# N32H49X register map
Vendor: Nsingtech Ltd.; File version: 1.0
Registers are 32-bit, read-write, reset 0x0 unless marked. A register's access mark holds for its fields unless they carry their own. Offsets are from the block's base; [hi:lo] are bit positions; {n}, {i} and the like mark numbered series.

## GTIM1 — General purpose timer 1
Base 0x40002C00
Same registers: GTIM4 0x40003800
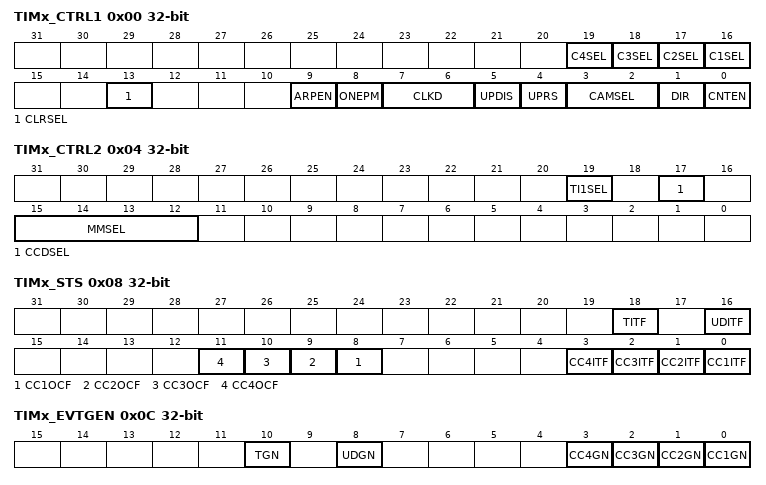
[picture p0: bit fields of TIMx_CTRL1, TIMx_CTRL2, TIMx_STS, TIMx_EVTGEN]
0x00 TIMx_CTRL1
  [n+15] C{n}SEL (n=1..4), [13] CLRSEL, [9] ARPEN, [8] ONEPM, [7:6] CLKD, [5] UPDIS, [4] UPRS, [3:2] CAMSEL, [1] DIR, [0] CNTEN
0x04 TIMx_CTRL2
  [19] TI1SEL, [17] CCDSEL, [15:12] MMSEL
0x08 TIMx_STS
  [18] TITF, [16] UDITF, [n+7] CC{n}OCF (n=1..4), [n-1] CC{n}ITF (n=1..4)
0x0C TIMx_EVTGEN
  [10] TGN, [8] UDGN, [n-1] CC{n}GN (n=1..4)
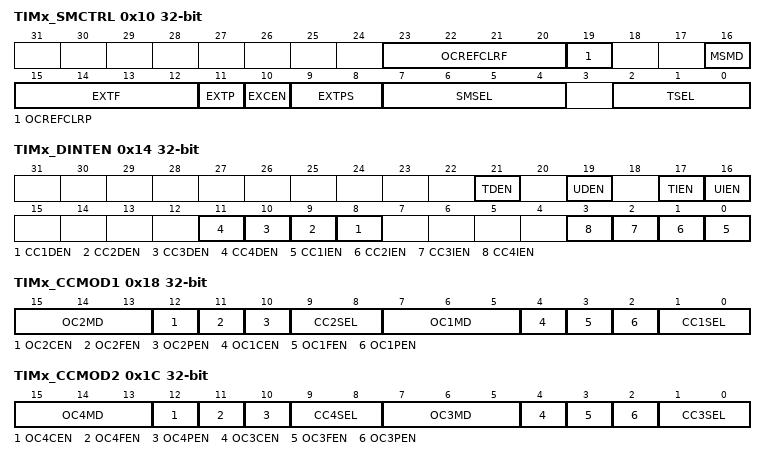
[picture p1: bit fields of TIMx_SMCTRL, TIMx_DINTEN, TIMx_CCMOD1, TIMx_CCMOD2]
0x10 TIMx_SMCTRL
  [23:20] OCREFCLRF, [19] OCREFCLRP, [16] MSMD, [15:12] EXTF, [11] EXTP, [10] EXCEN, [9:8] EXTPS, [7:4] SMSEL, [2:0] TSEL
0x14 TIMx_DINTEN
  [21] TDEN, [19] UDEN, [17] TIEN, [16] UIEN, [n+7] CC{n}DEN (n=1..4), [n-1] CC{n}IEN (n=1..4)
0x18 TIMx_CCMOD1
  [15:13] OC2MD, [12] OC2CEN, [11] OC2FEN, [10] OC2PEN, [9:8] CC2SEL, [7:5] OC1MD, [4] OC1CEN, [3] OC1FEN, [2] OC1PEN, [1:0] CC1SEL
0x1C TIMx_CCMOD2
  [15:13] OC4MD, [12] OC4CEN, [11] OC4FEN, [10] OC4PEN, [9:8] CC4SEL, [7:5] OC3MD, [4] OC3CEN, [3] OC3FEN, [2] OC3PEN, [1:0] CC3SEL
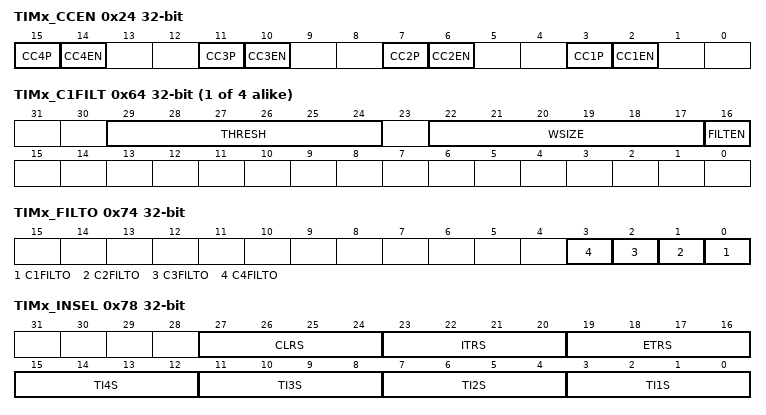
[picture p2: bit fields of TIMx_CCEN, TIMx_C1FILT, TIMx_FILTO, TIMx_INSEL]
0x24 TIMx_CCEN
  [4n-1] CC{n}P (n=1..4), [4n-2] CC{n}EN (n=1..4)
{0x24+4i} TIMx_CCDAT{i} (i=1..4)
0x40 TIMx_PSC
0x44 TIMx_AR reset 0xFFFF
0x48 TIMx_CNT
{0x60+4i} TIMx_C{i}FILT (i=1..4)
  [29:24] THRESH, [22:17] WSIZE, [16] FILTEN
0x74 TIMx_FILTO
  [n-1] C{n}FILTO (n=1..4)
0x78 TIMx_INSEL
  [27:24] CLRS, [23:20] ITRS, [19:16] ETRS, [4n-1:4n-4] TI{n}S (n=1..4)
0x88 TIMx_SLIDFPSC
  [15:0] SLIDFPSC
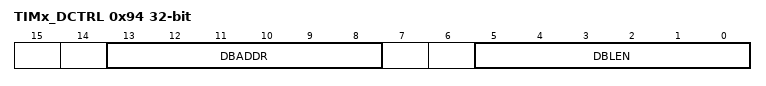
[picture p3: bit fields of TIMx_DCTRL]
0x94 TIMx_DCTRL
  [13:8] DBADDR, [5:0] DBLEN
0x98 TIMx_DADDR
  [31:0] BURST

## GTIM2 — General purpose timer 2
Base 0x40003000
Same registers: GTIM3 0x40003400, GTIM5 0x40005C00, GTIM6 0x40006000, GTIM7 0x40006400
Registers as GTIM1; these are added or differ:
{0x24+4i} TIMx_CCDAT{i} (i=1..4)
  [15:0] CCDAT{i}
0x40 TIMx_PSC
  [15:0] PSC
0x44 TIMx_AR reset 0xFFFF
  [15:0] AR
0x48 TIMx_CNT
  [15:0] CNT

## GTIM8 — General purpose timer 8
Base 0x40010C00
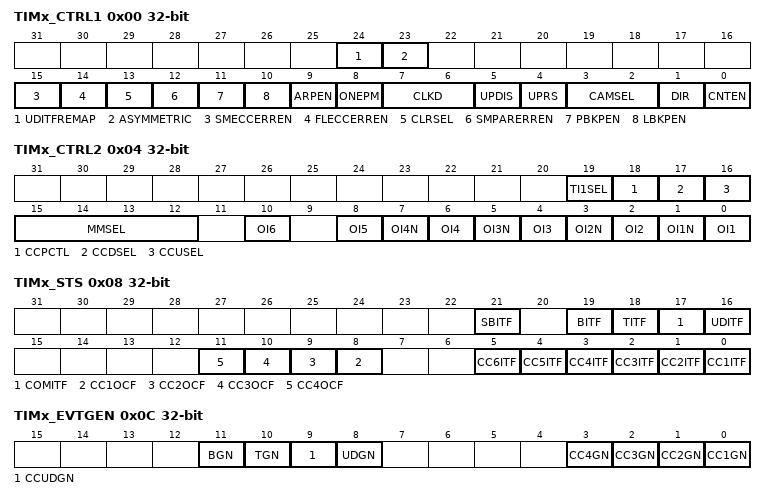
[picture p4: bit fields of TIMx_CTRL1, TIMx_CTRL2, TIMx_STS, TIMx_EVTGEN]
0x00 TIMx_CTRL1
  [24] UDITFREMAP, [23] ASYMMETRIC, [15] SMECCERREN, [14] FLECCERREN, [13] CLRSEL, [12] SMPARERREN, [11] PBKPEN, [10] LBKPEN, [9] ARPEN, [8] ONEPM, [7:6] CLKD, [5] UPDIS, [4] UPRS, [3:2] CAMSEL, [1] DIR, [0] CNTEN
0x04 TIMx_CTRL2
  [19] TI1SEL, [18] CCPCTL, [17] CCDSEL, [16] CCUSEL, [15:12] MMSEL, [2n-2] OI{n} (n=1..6), [2n-1] OI{n}N (n=1..4)
0x08 TIMx_STS
  [21] SBITF, [19] BITF, [18] TITF, [17] COMITF, [16] UDITF, [n+7] CC{n}OCF (n=1..4), [n-1] CC{n}ITF (n=1..6)
0x0C TIMx_EVTGEN
  [11] BGN, [10] TGN, [9] CCUDGN, [8] UDGN, [n-1] CC{n}GN (n=1..4)
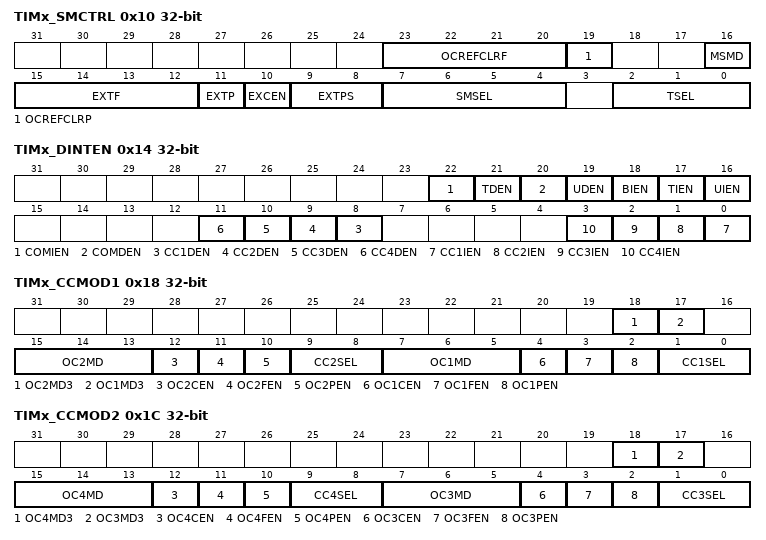
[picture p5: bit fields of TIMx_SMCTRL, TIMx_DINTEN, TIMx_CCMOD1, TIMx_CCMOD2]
0x10 TIMx_SMCTRL
  [23:20] OCREFCLRF, [19] OCREFCLRP, [16] MSMD, [15:12] EXTF, [11] EXTP, [10] EXCEN, [9:8] EXTPS, [7:4] SMSEL, [2:0] TSEL
0x14 TIMx_DINTEN
  [22] COMIEN, [21] TDEN, [20] COMDEN, [19] UDEN, [18] BIEN, [17] TIEN, [16] UIEN, [n+7] CC{n}DEN (n=1..4), [n-1] CC{n}IEN (n=1..4)
0x18 TIMx_CCMOD1
  [18] OC2MD3, [17] OC1MD3, [15:13] OC2MD, [12] OC2CEN, [11] OC2FEN, [10] OC2PEN, [9:8] CC2SEL, [7:5] OC1MD, [4] OC1CEN, [3] OC1FEN, [2] OC1PEN, [1:0] CC1SEL
0x1C TIMx_CCMOD2
  [18] OC4MD3, [17] OC3MD3, [15:13] OC4MD, [12] OC4CEN, [11] OC4FEN, [10] OC4PEN, [9:8] CC4SEL, [7:5] OC3MD, [4] OC3CEN, [3] OC3FEN, [2] OC3PEN, [1:0] CC3SEL
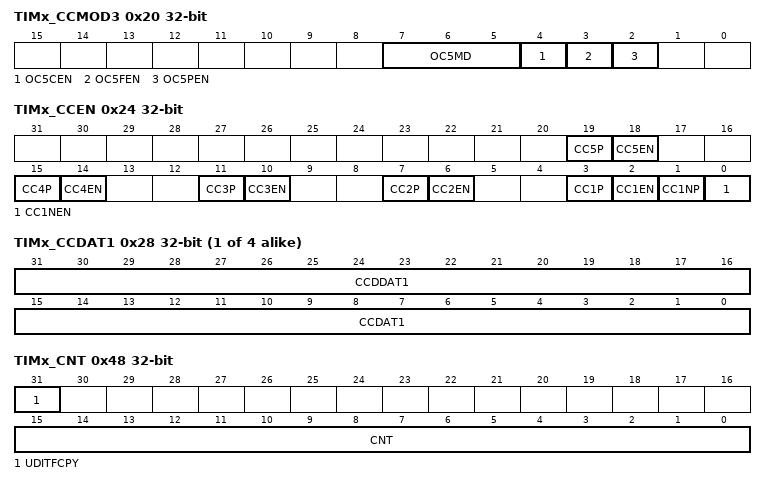
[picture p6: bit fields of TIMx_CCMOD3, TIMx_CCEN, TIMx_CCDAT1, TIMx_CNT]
0x20 TIMx_CCMOD3
  [7:5] OC5MD, [4] OC5CEN, [3] OC5FEN, [2] OC5PEN
0x24 TIMx_CCEN
  [4n-1] CC{n}P (n=1..5), [4n-2] CC{n}EN (n=1..5), [1] CC1NP, [0] CC1NEN
{0x24+4i} TIMx_CCDAT{i} (i=1..4)
  [31:16] CCDDAT{i}, [15:0] CCDAT{i}
0x38 TIMx_CCDAT5
  [15:0] CCDAT5
0x40 TIMx_PSC
  [15:0] PSC
0x44 TIMx_AR reset 0xFFFF
  [15:0] AR
0x48 TIMx_CNT
  [31] UDITFCPY, [15:0] CNT
0x4C TIMx_REPCNT
  [7:0] REPCNT
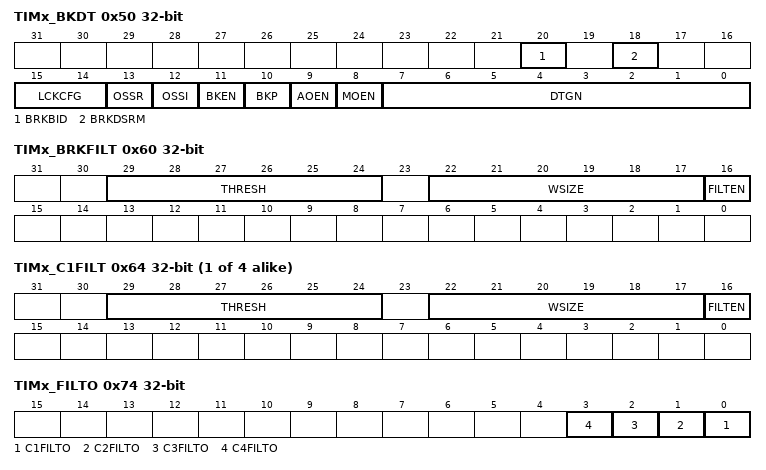
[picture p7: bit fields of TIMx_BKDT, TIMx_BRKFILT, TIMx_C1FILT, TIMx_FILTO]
0x50 TIMx_BKDT
  [20] BRKBID, [18] BRKDSRM, [15:14] LCKCFG, [13] OSSR, [12] OSSI, [11] BKEN, [10] BKP, [9] AOEN, [8] MOEN, [7:0] DTGN
0x60 TIMx_BRKFILT
  [29:24] THRESH, [22:17] WSIZE, [16] FILTEN
{0x60+4i} TIMx_C{i}FILT (i=1..4)
  [29:24] THRESH, [22:17] WSIZE, [16] FILTEN
0x74 TIMx_FILTO
  [n-1] C{n}FILTO (n=1..4)
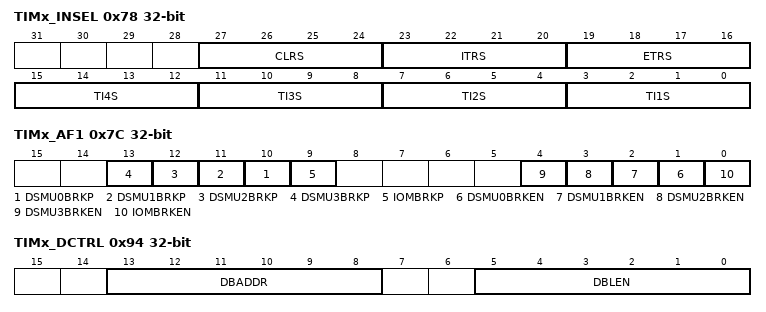
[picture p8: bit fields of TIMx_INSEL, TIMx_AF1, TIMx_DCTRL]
0x78 TIMx_INSEL
  [27:24] CLRS, [23:20] ITRS, [19:16] ETRS, [4n-1:4n-4] TI{n}S (n=1..4)
0x7C TIMx_AF1
  [n+10] DSMU{n}BRKP (n=0..3), [9] IOMBRKP, [n+1] DSMU{n}BRKEN (n=0..3), [0] IOMBRKEN
0x88 TIMx_SLIDFPSC
  [15:0] SLIDFPSC
0x94 TIMx_DCTRL
  [13:8] DBADDR, [5:0] DBLEN
0x98 TIMx_DADDR
  [31:0] BURST

## GTIM9 — General purpose timer 9
Base 0x40011000
Same registers: GTIM10 0x40011400
Registers as GTIM8; these are added or differ:
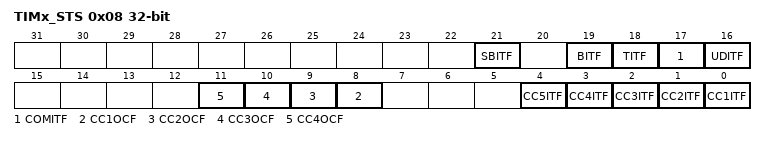
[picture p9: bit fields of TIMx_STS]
0x08 TIMx_STS
  [21] SBITF, [19] BITF, [18] TITF, [17] COMITF, [16] UDITF, [n+7] CC{n}OCF (n=1..4), [n-1] CC{n}ITF (n=1..5)
